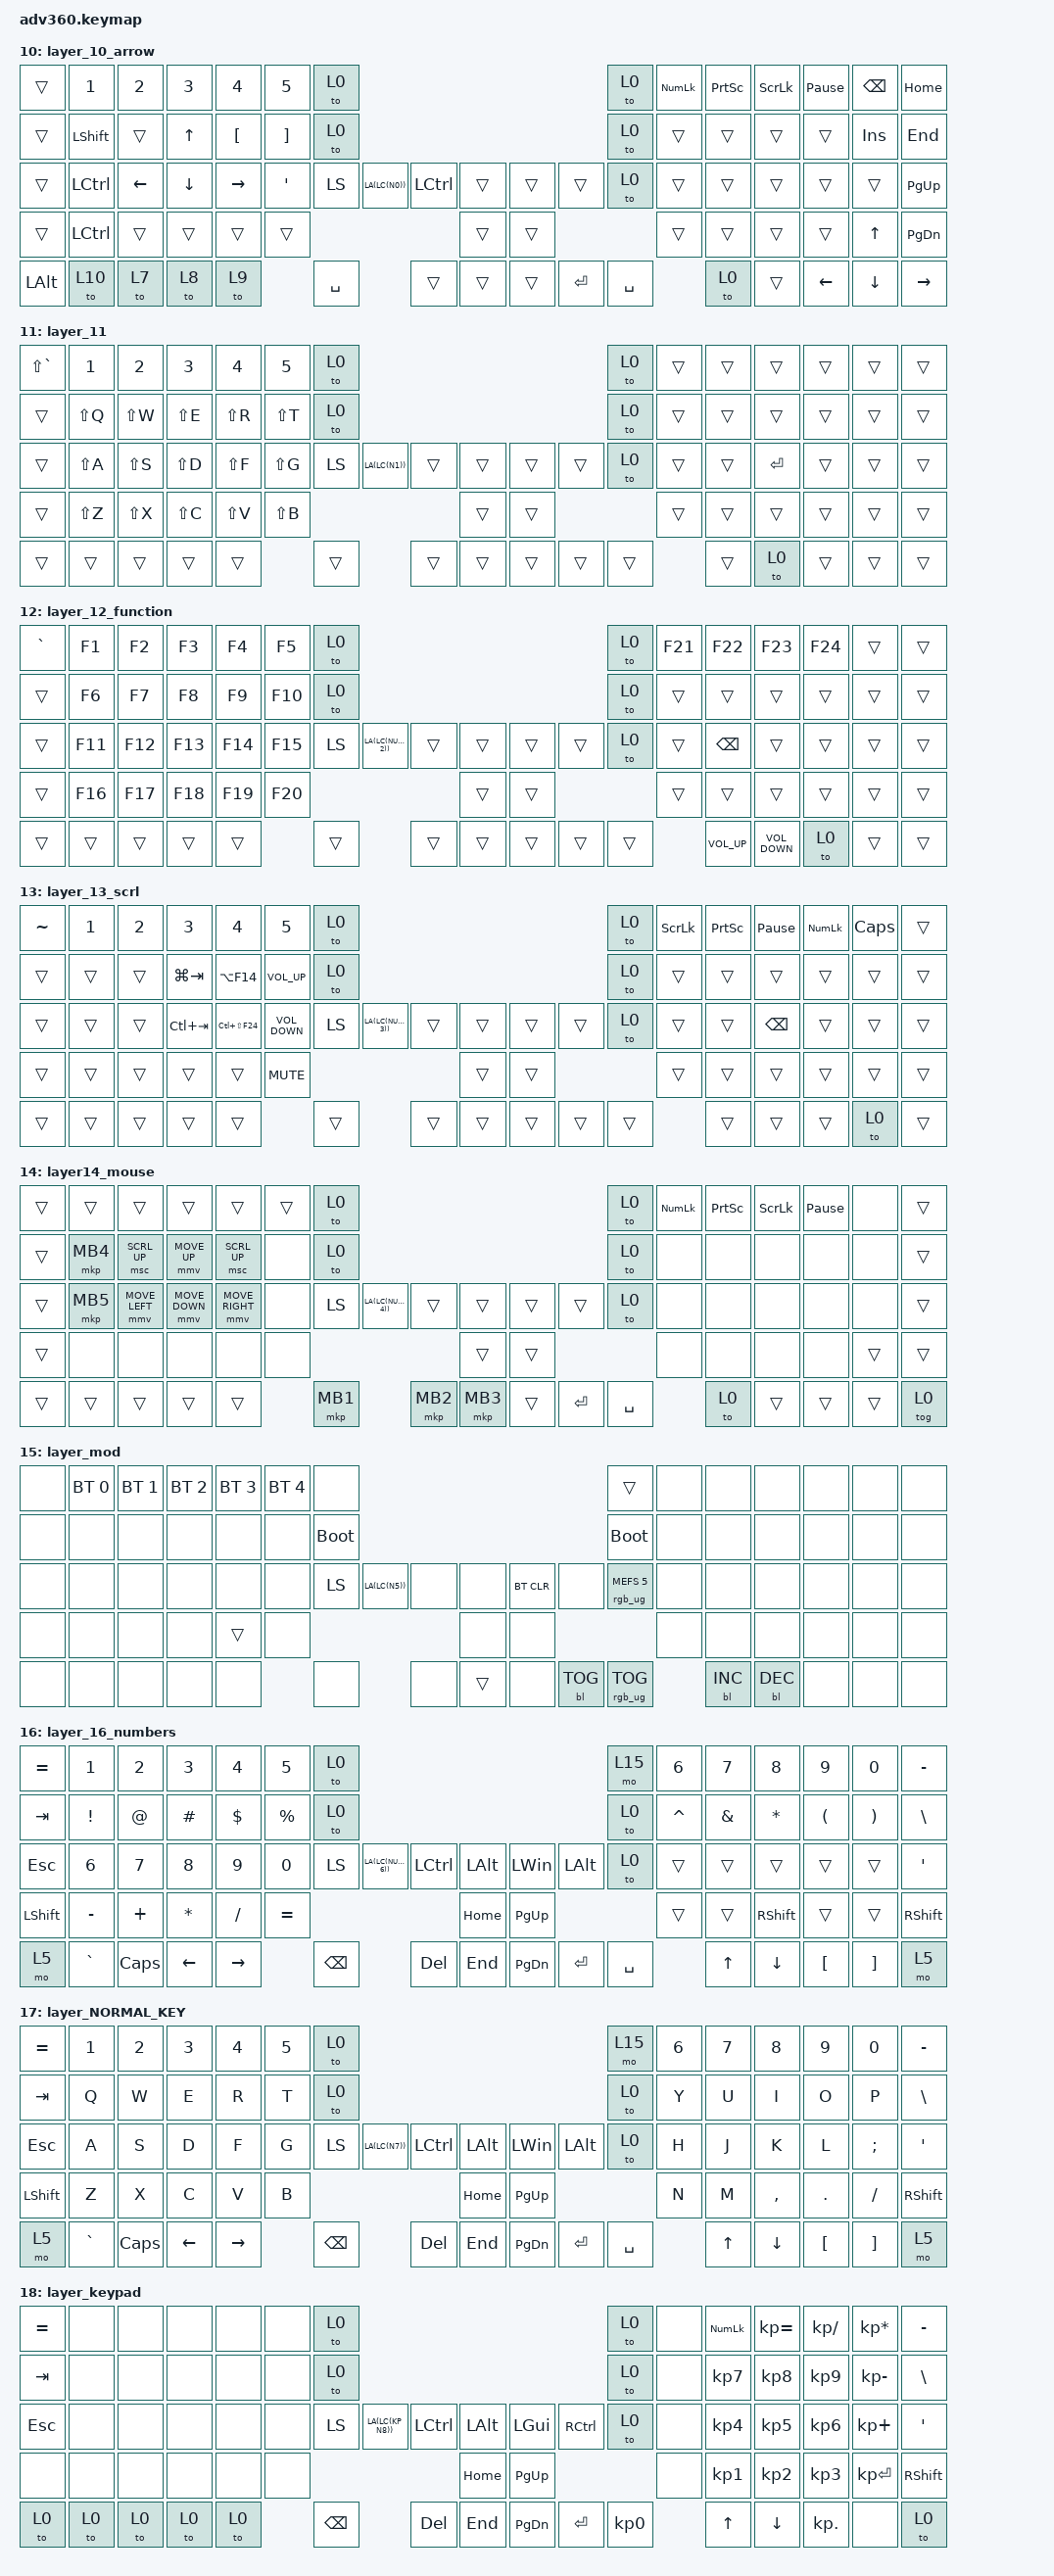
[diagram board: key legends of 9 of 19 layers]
/*
 * Copyright (c) 2020 The ZMK Contributors
 *
 * SPDX-License-Identifier: MIT
 */
/* THIS FILE WAS GENERATED!
 *
 * This file was generated automatically. You may or may not want to
 * edit it directly.
 */

#include <behaviors.dtsi>
#include <dt-bindings/zmk/backlight.h>
#include <dt-bindings/zmk/bt.h>
#include <dt-bindings/zmk/keys.h>
#include <dt-bindings/zmk/pointing.h>
#include <dt-bindings/zmk/rgb.h>

/ {
    behaviors {
        #include "macros.dtsi"
    #include "version.dtsi"
    };

    macros {
        dots: new_macro {
            compatible = "zmk,behavior-macro";
            #binding-cells = <0>;
            bindings = <&kp PERIOD &kp PERIOD &kp PERIOD>;
            label = "NEW_MACRO";
        };

        alt_shfit: alt_shfit {
            compatible = "zmk,behavior-macro";
            #binding-cells = <0>;
            bindings = <&kp LA(LEFT_SHIFT)>;
            label = "ALT_SHFIT";
        };
    };

    keymap {
        compatible = "zmk,keymap";

        default_layer {
            bindings = <
&to 1  &kp N1  &kp LS(T)  &kp N3   &kp N4    &kp N5  &to 18                                                                   &mo 15     &kp N6  &kp N7    &kp LS(O)  &kp LS(P)  &kp N0        &kp MINUS
&to 2  &kp Q   &kp W      &kp E    &kp R     &kp T   &to 14                                                                   &to 16     &kp Y   &kp U     &kp I      &kp O      &kp P         &kp BSLH
&to 3  &kp A   &lt 2 S    &lt 3 D  &lt 4 F   &kp G   &kp LA(LC(KP_N0))  &kp LCTRL  &kp LALT          &kp LGUI      &kp RALT   &to 17     &kp H   &lt 11 J  &lt 12 K   &lt 13 L   &kp RSHFT     &kp DQT
&to 4  &kp Z   &kp X      &kp C    &lt 16 V  &kp B                                 &kp TAB           &kp CAPSLOCK                        &kp N   &lt 16 M  &kp COMMA  &kp DOT    &kp QUESTION  &kp SEMICOLON
&to 5  &to 6   &to 7      &to 7    &to 9             &kp BSPC           &kp DEL    &kp LEFT_WIN      &kp ESCAPE    &kp ENTER  &kp SPACE          &to 10    &to 11     &to 12     &to 13        &mo 14
            >;
        };

        layer1_mouse {
            bindings = <
&to 0   &none   &none           &mkp MB3        &none            &none   &to 0                                                            &to 0     &trans    &trans          &mkp MB3        &mkp MB5         &trans         &trans
&trans  &none   &none           &mmv MOVE_UP    &none            &none   &to 0                                                            &to 0     &mkp MB3  &mkp MB2        &mmv MOVE_UP    &mkp MB4         &none          &trans
&trans  &none   &mmv MOVE_LEFT  &mmv MOVE_DOWN  &mmv MOVE_RIGHT  &trans  &kp LA(LC(KP_NUMBER_1))  &trans    &trans      &trans  &trans    &to 0     &mkp MB1  &mmv MOVE_LEFT  &mmv MOVE_DOWN  &mmv MOVE_RIGHT  &kp K_MENU     &trans
&trans  &trans  &trans          &trans          &trans           &trans                                     &trans      &trans                      &none     &kp UP_ARROW    &kp DOWN_ARROW  &kp PG_UP        &kp PG_DN      &trans
&trans  &trans  &trans          &trans          &trans                   &mkp MB1                 &mkp MB2  &trans      &trans  &mkp MB2  &mkp MB1            &none           &none           &kp LC(W)        &kp LS(LC(T))  &trans
            >;
        };

        layer2_arrows {
            bindings = <
&trans  &kp GRAVE  &trans           &trans        &trans     &trans       &to 0                                                     &to 0   &kp NUMBER_6  &kp N7         &kp N8         &kp N9            &kp N0     &kp UNDERSCORE
&to 0   &trans     &kp LS(LC(TAB))  &kp TAB       &kp BSPC   &kp LG(TAB)  &to 0                                                     &to 0   &kp END       &kp BACKSPACE  &kp UP         &kp DEL           &kp PG_UP  &kp PIPE
&to 0   &trans     &trans           &kp LCTRL     &kp LSHFT  &kp LA(TAB)  &kp LA(LC(KP_N2))  &trans   &trans        &trans  &trans  &to 0   &kp HOME      &kp LEFT       &kp DOWN       &kp RIGHT         &kp PG_DN  &kp SINGLE_QUOTE
&trans  &none      &none            &kp LEFT_ALT  &kp RALT   &none                                    &trans        &trans                  &trans        &trans         &kp LESS_THAN  &kp GREATER_THAN  &kp SLASH  &kp COLON
&trans  &trans     &trans           &none         &kp LSHFT               &kp BACKSPACE      &kp DEL  &kp CAPS      &trans  &trans  &trans                &trans         &trans         &trans            &trans     &trans
            >;
        };

        layer3_symbols_left {
            bindings = <
&trans  &trans  &trans  &trans  &trans          &trans  &to 0                                                            &to 0   &kp CARET      &kp AMPERSAND         &kp ASTERISK           &kp LEFT_PARENTHESIS  &kp RIGHT_PARENTHESIS  &kp MINUS
&to 0   &none   &none   &none   &trans          &trans  &to 0                                                            &to 0   &kp EQUAL      &kp LEFT_PARENTHESIS  &kp RIGHT_PARENTHESIS  &kp LS(O)             &kp LS(P)              &kp PLUS
&to 0   &none   &none   &trans  &kp LEFT_SHIFT  &trans  &kp LA(LC(KP_N3))  &trans  &trans                &trans  &trans  &to 0   &kp SEMICOLON  &kp QUESTION          &kp EXCL               &kp SQT               &kp DQT                &kp NON_US_BACKSLASH
&trans  &none   &trans  &trans  &none           &trans                             &kp LA(CLCK)          &trans                  &kp EXCL       &kp MINUS             &kp TILDE              &dots                 &kp SLASH              &kp COLON
&trans  &trans  &trans  &trans  &to 0                   &trans             &trans  &kp LC(CAPSLOCK)      &trans  &trans  &trans                 &trans                &trans                 &trans                &trans                 &trans
            >;
        };

        layer4_leftshift {
            bindings = <
&kp TILDE  &none   &none   &none          &none   &none   &to 0                                                     &to 0          &kp LS(NUMBER_6)  &kp LS(N7)        &kp LS(N8)         &kp LS(N9)            &kp LS(N0)             &kp LS(MINUS)
&trans     &none   &none   &none          &none   &none   &to 0                                                     &to 0          &kp LS(Y)         &kp LS(U)         &kp LS(I)          &kp LS(O)             &kp LS(P)              &kp LS(NON_US_BACKSLASH)
&trans     &none   &none   &kp BACKSPACE  &none   &trans  &kp LA(LC(KP_N4))  &trans  &trans      &trans  &trans     &to 0          &kp LS(H)         &kp LS(J)         &kp LS(K)          &kp LS(L)             &kp LS(SEMICOLON)      &kp LS(SQT)
&to 0      &trans  &trans  &trans         &trans  &trans                             &trans      &trans                            &kp LS(N)         &kp LS(M)         &kp LS(COMMA)      &kp LS(PERIOD)        &kp LS(SLASH)          &trans
&trans     &trans  &trans  &trans         &trans          &trans             &trans  &trans      &trans  &kp LANG1  &kp RIGHT_ALT                    &kp LEFT_BRACKET  &kp RIGHT_BRACKET  &kp LS(LEFT_BRACKET)  &kp LS(RIGHT_BRACKET)  &trans
            >;
        };

        layer5_fn {
            bindings = <
&kp F1     &kp F2        &kp F3         &kp F4      &kp F5       &kp F6  &tog 0                                                 &to 0   &kp F7    &kp F8    &kp F9    &kp F10    &kp F11    &kp F12
&trans     &trans        &trans         &trans      &trans       &trans  &to 0                                                  &to 0   &kp HOME  &trans    &kp UP    &trans     &kp PG_UP  &kp BSLH
&trans     &kp K_SELECT  &kp C_AC_SAVE  &trans      &trans       &trans  &kp LA(LC(KP_N5))  &trans  &trans      &trans  &trans  &to 0   &kp END   &kp LEFT  &kp DOWN  &kp RIGHT  &kp PG_DN  &kp SQT
&kp LSHFT  &kp K_REDO    &kp K_CUT      &kp K_COPY  &kp K_PASTE  &trans                             &trans      &trans                  &trans    &trans    &trans    &trans     &kp SLASH  &trans
&to 0      &kp SPACE     &kp ENTER      &trans      &trans               &trans             &trans  &trans      &trans  &trans  &trans            &none     &none     &none      &trans     &trans
            >;
        };

        layer6_shortcuts {
            bindings = <
&trans  &kp LS(LA(LG(LC(NUMBER_1))))  &kp LS(LA(LC(LG(NUMBER_2))))  &kp LS(LA(LC(LG(NUMBER_3))))  &trans  &trans  &to 0                                                  &to 0   &trans  &kp PRINTSCREEN  &kp SCROLLLOCK  &kp PAUSE_BREAK  &trans  &trans
&trans  &trans                        &trans                        &trans                        &trans  &trans  &to 0                                                  &to 0   &trans  &trans           &trans          &trans           &trans  &trans
&trans  &trans                        &trans                        &trans                        &trans  &trans  &kp LA(LC(KP_N6))  &trans  &trans      &trans  &trans  &to 0   &trans  &trans           &trans          &trans           &trans  &trans
&trans  &kp LS(LC(LA(LG(Z))))         &kp LS(LA(LC(LG(X))))         &trans                        &trans  &trans                             &trans      &trans                  &trans  &trans           &trans          &trans           &trans  &trans
&trans  &to 0                         &to 7                         &to 8                         &to 9           &trans             &trans  &trans      &trans  &trans  &trans          &trans           &trans          &trans           &trans  &trans
            >;
        };

        layer_numbers {
            bindings = <
&kp GRAVE  &kp NUMBER_1     &kp NUMBER_2  &kp NUMBER_3  &kp NUMBER_4  &kp N5        &to 0                                                          &to 0      &kp NUMBER_6  &kp N7         &kp N8        &kp N9                &kp N0                 &kp MINUS
&kp TILDE  &kp EXCLAMATION  &kp AT_SIGN   &kp HASH      &kp DOLLAR    &kp PERCENT   &to 0                                                          &to 0      &kp LCTRL     &kp AMPERSAND  &kp ASTERISK  &kp LEFT_PARENTHESIS  &kp RIGHT_PARENTHESIS  &kp EQUAL
&kp GRAVE  &kp N1           &kp N2        &kp NUMBER_3  &kp NUMBER_4  &kp NUMBER_5  &kp LA(LC(KP_N7))  &trans   &trans      &trans      &trans     &to 0      &kp N6        &kp N7         &kp N8        &kp N9                &kp N0                 &kp RSHFT
&kp TILDE  &kp EXCL         &kp AT        &kp HASH      &kp DLLR      &kp PRCNT                                 &trans      &trans                            &kp CARET     &kp AMPERSAND  &kp ASTERISK  &kp PERIOD            &kp PERIOD             &trans
&trans     &trans           &to 0         &to 0         &to 0                       &kp BACKSPACE      &kp DEL  &trans      &kp ESCAPE  &kp ENTER  &kp SPACE                &trans         &kp DOWN      &kp UP                &kp LEFT               &kp RIGHT
            >;
        };

        layer_right_for_game {
            bindings = <
&kp GRAVE   &kp N1  &kp N2  &kp N3  &kp N4  &kp N5  &to 0                                                                    &mo 15     &kp N6  &kp N7  &kp N8     &kp N9            &kp N0             &kp MINUS
&kp TAB     &kp Q   &kp W   &kp E   &kp R   &kp T   &to 0                                                                    &to 0      &kp Y   &kp U   &kp I      &kp O             &kp P              &kp BACKSLASH
&kp ESC     &kp A   &kp S   &kp D   &kp F   &kp G   &kp LA(LC(KP_N8))  &kp LCTRL  &kp RALT         &kp LEFT_WIN   &kp LALT   &to 0      &kp H   &kp J   &kp K      &kp L             &kp SEMICOLON      &kp SQT
&kp LSHIFT  &kp Z   &kp X   &kp C   &kp V   &kp B                                 &kp LG(TAB)      &kp PAGE_UP                          &kp N   &kp M   &kp COMMA  &kp DOT           &kp SLASH          &kp RSHFT
&kp LALT    &to 10  &to 7   &to 8   &to 9           &kp SPACE          &kp ENTER  &kp ESC          &kp PAGE_DOWN  &kp ENTER  &kp SPACE          &kp UP  &kp DOWN   &kp LEFT_BRACKET  &kp RIGHT_BRACKET  &mo 5
            >;
        };

        layer9_THUMB_FUN1TEST {
            bindings = <
&kp GRAVE     &kp NUMBER_1      &kp NUMBER_2  &kp NUMBER_3  &kp NUMBER_4  &kp N5         &to 0                                                                    &mo 15     &kp N6  &kp N7  &kp N8     &kp N9            &kp N0             &kp MINUS
&kp TAB       &kp LANG_HANGEUL  &kp LANG2     &kp LANG3     &kp LANG4     &kp LANG5      &to 0                                                                    &to 0      &kp Y   &kp U   &kp I      &kp O             &kp P              &kp BACKSLASH
&kp ESC       &kp H             &kp J         &kp K         &kp L         &kp SEMICOLON  &kp LA(LC(KP_N9))  &kp LCTRL  &kp RALT         &kp LEFT_WIN   &kp LALT   &to 0      &kp H   &kp J   &kp K      &kp L             &kp SEMICOLON      &kp SQT
&kp LSHIFT    &kp N             &kp M         &kp COMMA     &kp PERIOD    &kp SLASH                                    &kp LG(TAB)      &kp PAGE_UP                          &kp N   &kp M   &kp COMMA  &kp DOT           &kp SLASH          &kp RSHFT
&kp LEFT_ALT  &to 0             &to 0         &to 0         &to 0                        &kp SPACE          &kp ENTER  &kp ESC          &kp PAGE_DOWN  &kp ENTER  &kp SPACE          &kp UP  &kp DOWN   &kp LEFT_BRACKET  &kp RIGHT_BRACKET  &mo 5
            >;
        };

        layer_10_arrow {
            bindings = <
&trans    &kp NUMBER_1  &kp NUMBER_2    &kp NUMBER_3    &kp NUMBER_4      &kp N5             &to 0                                                         &to 0      &kp KP_NUMLOCK  &kp PRINTSCREEN  &kp SCROLLLOCK  &kp PAUSE_BREAK  &kp BACKSPACE   &kp HOME
&trans    &kp LSHFT     &trans          &kp UP_ARROW    &kp LEFT_BRACKET  &kp RIGHT_BRACKET  &to 0                                                         &to 0      &trans          &trans           &trans          &trans           &kp INSERT      &kp END
&trans    &kp LCTRL     &kp LEFT_ARROW  &kp DOWN_ARROW  &kp RIGHT_ARROW   &kp SQT            &kp LS(LA(LC(N0)))  &kp LCTRL  &trans      &trans  &trans     &to 0      &trans          &trans           &trans          &trans           &trans          &kp PG_UP
&trans    &kp LCTRL     &trans          &trans          &trans            &trans                                            &trans      &trans                        &trans          &trans           &trans          &trans           &kp UP_ARROW    &kp PG_DN
&kp LALT  &to 10        &to 7           &to 8           &to 9                                &kp SPACE           &trans     &trans      &trans  &kp ENTER  &kp SPACE                  &to 0            &trans          &kp LEFT_ARROW   &kp DOWN_ARROW  &kp RIGHT_ARROW
            >;
        };

        layer_11 {
            bindings = <
&kp LS(GRAVE)  &kp NUMBER_1  &kp NUMBER_2  &kp NUMBER_3  &kp NUMBER_4  &kp N5     &to 0                                                   &to 0   &trans  &trans  &trans     &trans  &trans  &trans
&trans         &kp LS(Q)     &kp LS(W)     &kp LS(E)     &kp LS(R)     &kp LS(T)  &to 0                                                   &to 0   &trans  &trans  &trans     &trans  &trans  &trans
&trans         &kp LS(A)     &kp LS(S)     &kp LS(D)     &kp LS(F)     &kp LS(G)  &kp LS(LA(LC(N1)))  &trans  &trans      &trans  &trans  &to 0   &trans  &trans  &kp ENTER  &trans  &trans  &trans
&trans         &kp LS(Z)     &kp LS(X)     &kp LS(C)     &kp LS(V)     &kp LS(B)                              &trans      &trans                  &trans  &trans  &trans     &trans  &trans  &trans
&trans         &trans        &trans        &trans        &trans                   &trans              &trans  &trans      &trans  &trans  &trans          &trans  &to 0      &trans  &trans  &trans
            >;
        };

        layer_12_function {
            bindings = <
&kp GRAVE  &kp F1   &kp F2   &kp F3   &kp F4   &kp F5   &to 0                                                         &to 0   &kp F21  &kp F22          &kp F23            &kp F24  &trans  &trans
&trans     &kp F6   &kp F7   &kp F8   &kp F9   &kp F10  &to 0                                                         &to 0   &trans   &trans           &trans             &trans   &trans  &trans
&trans     &kp F11  &kp F12  &kp F13  &kp F14  &kp F15  &kp LS(LA(LC(NUMBER_2)))  &trans  &trans      &trans  &trans  &to 0   &trans   &kp BACKSPACE    &trans             &trans   &trans  &trans
&trans     &kp F16  &kp F17  &kp F18  &kp F19  &kp F20                                    &trans      &trans                  &trans   &trans           &trans             &trans   &trans  &trans
&trans     &trans   &trans   &trans   &trans            &trans                    &trans  &trans      &trans  &trans  &trans           &kp K_VOLUME_UP  &kp K_VOLUME_DOWN  &to 0    &trans  &trans
            >;
        };

        layer_13_scrl {
            bindings = <
&kp TILDE  &kp NUMBER_1  &kp NUMBER_2  &kp NUMBER_3  &kp NUMBER_4     &kp N5             &to 0                                                         &to 0   &kp SCROLLLOCK  &kp PRINTSCREEN  &kp PAUSE_BREAK  &kp KP_NUMLOCK  &kp CLCK  &trans
&trans     &trans        &trans        &kp LG(TAB)   &kp LA(F14)      &kp K_VOLUME_UP    &to 0                                                         &to 0   &trans          &trans           &trans           &trans          &trans    &trans
&trans     &trans        &trans        &kp LC(TAB)   &kp LC(LS(F24))  &kp K_VOLUME_DOWN  &kp LS(LA(LC(NUMBER_3)))  &trans  &trans      &trans  &trans  &to 0   &trans          &trans           &kp BACKSPACE    &trans          &trans    &trans
&trans     &trans        &trans        &trans        &trans           &kp K_MUTE                                           &trans      &trans                  &trans          &trans           &trans           &trans          &trans    &trans
&trans     &trans        &trans        &trans        &trans                              &trans                    &trans  &trans      &trans  &trans  &trans                  &trans           &trans           &trans          &to 0     &trans
            >;
        };

        layer14_mouse {
            bindings = <
&trans  &trans    &trans          &trans          &trans           &trans  &to 0                                                                &to 0      &kp KP_NUMLOCK  &kp PRINTSCREEN  &kp SCROLLLOCK  &kp PAUSE_BREAK  &none   &trans
&trans  &mkp MB4  &msc SCRL_UP    &mmv MOVE_UP    &msc SCRL_UP     &none   &to 0                                                                &to 0      &none           &none            &none           &none            &none   &trans
&trans  &mkp MB5  &mmv MOVE_LEFT  &mmv MOVE_DOWN  &mmv MOVE_RIGHT  &none   &kp LS(LA(LC(NUMBER_4)))  &trans    &trans        &trans  &trans     &to 0      &none           &none            &none           &none            &none   &trans
&trans  &none     &none           &none           &none            &none                                       &trans        &trans                        &none           &none            &none           &none            &trans  &trans
&trans  &trans    &trans          &trans          &trans                   &mkp MB1                  &mkp MB2  &mkp MB3      &trans  &kp ENTER  &kp SPACE                  &to 0            &trans          &trans           &trans  &tog 0
            >;
        };

        layer_mod {
            bindings = <
&none  &bt BT_SEL 0  &bt BT_SEL 1  &bt BT_SEL 2  &bt BT_SEL 3  &bt BT_SEL 4  &none                                                          &trans                  &none  &none       &none       &none  &none  &none
&none  &none         &none         &none         &none         &none         &bootloader                                                    &bootloader             &none  &none       &none       &none  &none  &none
&none  &none         &none         &none         &none         &none         &kp LS(LA(LC(N5)))  &none  &none       &bt BT_CLR  &none       &rgb_ug RGB_MEFS_CMD 5  &none  &none       &none       &none  &none  &none
&none  &none         &none         &none         &trans        &none                                    &none       &none                                           &none  &none       &none       &none  &none  &none
&none  &none         &none         &none         &none                       &none               &none  &trans      &none       &bl BL_TOG  &rgb_ug RGB_TOG                &bl BL_INC  &bl BL_DEC  &none  &none  &none
            >;
        };

        layer_16_numbers {
            bindings = <
&kp EQUAL   &kp N1           &kp N2       &kp N3        &kp N4      &kp N5       &to 0                                                                        &mo 15     &kp N6     &kp N7         &kp N8        &kp N9                &kp N0                 &kp MINUS
&kp TAB     &kp EXCLAMATION  &kp AT_SIGN  &kp HASH      &kp DOLLAR  &kp PERCENT  &to 0                                                                        &to 0      &kp CARET  &kp AMPERSAND  &kp ASTERISK  &kp LEFT_PARENTHESIS  &kp RIGHT_PARENTHESIS  &kp BACKSLASH
&kp ESC     &kp NUMBER_6     &kp N7       &kp N8        &kp N9      &kp N0       &kp LS(LA(LC(NUMBER_6)))  &kp LCTRL  &kp LALT      &kp LEFT_WIN   &kp LALT   &to 0      &trans     &trans         &trans        &trans                &trans                 &kp SQT
&kp LSHIFT  &kp MINUS        &kp PLUS     &kp ASTERISK  &kp SLASH   &kp EQUAL                                         &kp HOME      &kp PAGE_UP                          &trans     &trans         &kp RSHFT     &trans                &trans                 &kp RSHFT
&mo 5       &kp GRAVE        &kp CAPS     &kp LEFT      &kp RIGHT                &kp BSPC                  &kp DEL    &kp END       &kp PAGE_DOWN  &kp ENTER  &kp SPACE             &kp UP         &kp DOWN      &kp LEFT_BRACKET      &kp RIGHT_BRACKET      &mo 5
            >;
        };

        layer_NORMAL_KEY {
            bindings = <
&kp EQUAL   &kp N1     &kp N2    &kp N3    &kp N4     &kp N5  &to 0                                                                  &mo 15     &kp N6  &kp N7  &kp N8     &kp N9            &kp N0             &kp MINUS
&kp TAB     &kp Q      &kp W     &kp E     &kp R      &kp T   &to 0                                                                  &to 0      &kp Y   &kp U   &kp I      &kp O             &kp P              &kp BACKSLASH
&kp ESC     &kp A      &kp S     &kp D     &kp F      &kp G   &kp LS(LA(LC(N7)))  &kp LCTRL  &kp LALT      &kp LEFT_WIN   &kp LALT   &to 0      &kp H   &kp J   &kp K      &kp L             &kp SEMICOLON      &kp SQT
&kp LSHIFT  &kp Z      &kp X     &kp C     &kp V      &kp B                                  &kp HOME      &kp PAGE_UP                          &kp N   &kp M   &kp COMMA  &kp DOT           &kp SLASH          &kp RSHFT
&mo 5       &kp GRAVE  &kp CAPS  &kp LEFT  &kp RIGHT          &kp BSPC            &kp DEL    &kp END       &kp PAGE_DOWN  &kp ENTER  &kp SPACE          &kp UP  &kp DOWN   &kp LEFT_BRACKET  &kp RIGHT_BRACKET  &mo 5
            >;
        };

        layer_keypad {
            bindings = <
&kp EQUAL  &none  &none  &none  &none  &none  &to 0                                                                 &to 0      &none  &kp KP_NUM  &kp KP_EQUAL  &kp KP_DIVIDE  &kp KP_MULTIPLY  &kp MINUS
&kp TAB    &none  &none  &none  &none  &none  &to 0                                                                 &to 0      &none  &kp KP_N7   &kp KP_N8     &kp KP_N9      &kp KP_MINUS     &kp BSLH
&kp ESC    &none  &none  &none  &none  &none  &kp LS(LA(LC(KP_N8)))  &kp LCTRL  &kp LALT      &kp LGUI   &kp RCTRL  &to 0      &none  &kp KP_N4   &kp KP_N5     &kp KP_N6      &kp KP_PLUS      &kp SQT
&none      &none  &none  &none  &none  &none                                    &kp HOME      &kp PG_UP                        &none  &kp KP_N1   &kp KP_N2     &kp KP_N3      &kp KP_ENTER     &kp RSHFT
&to 0      &to 0  &to 0  &to 0  &to 0         &kp BSPC               &kp DEL    &kp END       &kp PG_DN  &kp ENTER  &kp KP_N0         &kp UP      &kp DOWN      &kp KP_DOT     &none            &to 0
            >;
        };
    };
};
